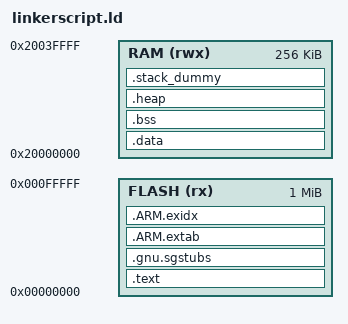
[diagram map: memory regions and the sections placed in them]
OUTPUT_FORMAT ("elf32-littlearm", "elf32-bigarm", "elf32-littlearm")

ENTRY(Reset_Handler)

MEMORY
{
  FLASH (rx) : ORIGIN = 0x0, LENGTH = 0x100000
  RAM (rwx) :  ORIGIN = 0x20000000, LENGTH = 0x40000
}

SECTIONS
{
    .text :
    {
        KEEP(*(.isr_vector))
        *(.text*)

        KEEP(*(.init))
        KEEP(*(.fini))

        /* .ctors */
        *crtbegin.o(.ctors)
        *crtbegin?.o(.ctors)
        *(EXCLUDE_FILE(*crtend?.o *crtend.o) .ctors)
        *(SORT(.ctors.*))
        *(.ctors)

        /* .dtors */
        *crtbegin.o(.dtors)
        *crtbegin?.o(.dtors)
        *(EXCLUDE_FILE(*crtend?.o *crtend.o) .dtors)
        *(SORT(.dtors.*))
        *(.dtors)

        *(.rodata*)

        KEEP(*(.eh_frame*))
    } > FLASH

    .gnu.sgstubs :
    {
        . = ALIGN(32);
    } > FLASH
    

    .ARM.extab : 
    {
        *(.ARM.extab* .gnu.linkonce.armextab.*)
    } > FLASH

    
    .ARM.exidx :
    {
        __exidx_start = .;
        *(.ARM.exidx* .gnu.linkonce.armexidx.*)
        __exidx_end = .;
    } > FLASH

    . = ALIGN(4);
    __etext = .;

    .data : AT (__etext)
    {
        __data_start__ = .;
        *(vtable)
        *(.data*)

        . = ALIGN(4);
        PROVIDE_HIDDEN (__preinit_array_start = .);
        KEEP(*(.preinit_array))
        PROVIDE_HIDDEN (__preinit_array_end = .);

        . = ALIGN(4);
        PROVIDE_HIDDEN (__init_array_start = .);
        KEEP(*(SORT(.init_array.*)))
        KEEP(*(.init_array))
        PROVIDE_HIDDEN (__init_array_end = .);


        . = ALIGN(4);
        PROVIDE_HIDDEN (__fini_array_start = .);
        KEEP(*(SORT(.fini_array.*)))
        KEEP(*(.fini_array))
        PROVIDE_HIDDEN (__fini_array_end = .);

        KEEP(*(.jcr*))
        . = ALIGN(4);
        __data_end__ = .;
    } > RAM

    .bss :
    {
        . = ALIGN(4);
        __bss_start__ = .;
        *(.bss*)
        *(COMMON)
        . = ALIGN(4);
        __bss_end__ = .;
    } > RAM
    
    .heap (COPY):
    {
        __HeapBase = .;
        __end__ = .;
        PROVIDE(end = .);
        KEEP(*(.heap*))
        __HeapLimit = .;
    } > RAM

    .stack_dummy (COPY):
    {
        KEEP(*(.stack*))
    } > RAM

    __StackTop = ORIGIN(RAM) + LENGTH(RAM);
    __StackLimit = __StackTop - SIZEOF(.stack_dummy);
    PROVIDE(__stack = __StackTop);
}
